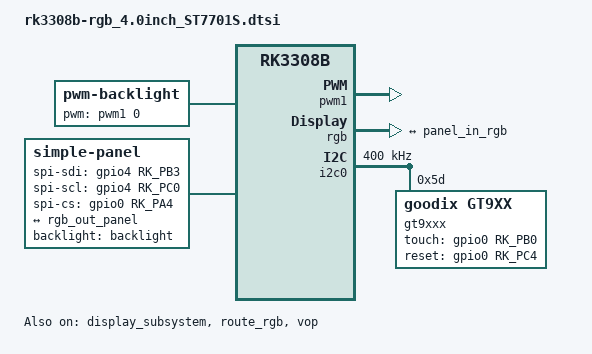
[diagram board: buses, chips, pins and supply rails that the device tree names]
// SPDX-License-Identifier: (GPL-2.0+ OR MIT)
/*
 * Copyright (c) 2018 Fuzhou Rockchip Electronics Co., Ltd
 *
 */

/ {
	backlight: backlight {
		status = "okay";
		compatible = "pwm-backlight";
		pwms = <&pwm1 0 50000 0>;
		brightness-levels = <
			  0   1   2   3   4   5   6   7
			  8   9  10  11  12  13  14  15
			 16  17  18  19  20  21  22  23
			 24  25  26  27  28  29  30  31
			 32  33  34  35  36  37  38  39
			 40  41  42  43  44  45  46  47
			 48  49  50  51  52  53  54  55
			 56  57  58  59  60  61  62  63
			 64  65  66  67  68  69  70  71
			 72  73  74  75  76  77  78  79
			 80  81  82  83  84  85  86  87
			 88  89  90  91  92  93  94  95
			 96  97  98  99 100 101 102 103
			104 105 106 107 108 109 110 111
			112 113 114 115 116 117 118 119
			120 121 122 123 124 125 126 127
			128 129 130 131 132 133 134 135
			136 137 138 139 140 141 142 143
			144 145 146 147 148 149 150 151
			152 153 154 155 156 157 158 159
			160 161 162 163 164 165 166 167
			168 169 170 171 172 173 174 175
			176 177 178 179 180 181 182 183
			184 185 186 187 188 189 190 191
			192 193 194 195 196 197 198 199
			200 201 202 203 204 205 206 207
			208 209 210 211 212 213 214 215
			216 217 218 219 220 221 222 223
			224 225 226 227 228 229 230 231
			232 233 234 235 236 237 238 239
			240 241 242 243 244 245 246 247
			248 249 250 251 252 253 254 255>;
		default-brightness-level = <200>;
	};

	panel: panel {
		compatible = "simple-panel";
		bus-format = <MEDIA_BUS_FMT_RGB888_1X24>;
		backlight = <&backlight>;
        init-delay-ms = <200>;
        rgb-mode = "p888";
		width-mm = <72>;
		height-mm = <72>;
		status = "okay";
        
        spi-sdi-gpios = <&gpio4 RK_PB3 GPIO_ACTIVE_HIGH>;
        spi-scl-gpios = <&gpio4 RK_PC0 GPIO_ACTIVE_HIGH>;
        spi-cs-gpios = <&gpio0 RK_PA4 GPIO_ACTIVE_HIGH>;

        pinctrl-names = "default";
        pinctrl-0 = <&spi_init_cmd>;
        rockchip,cmd-type = "spi";
        /* type:0 is cmd, 1 is data */
        panel-init-sequence = [
            /* type delay num val1 val2 val3 */                                                                                                                                                         
            00   78  01  11
            00   01  01  ff
            01   01  01  77
            01   01  01  01
            01   01  01  00
            01   01  01  00
            01   01  01  10

            00   01  01  c0
            01   01  01  3b
            01   01  01  00

            00   01  01  c1
            01   01  01  0d
            01   01  01  02

            00   01  01  c2
            01   01  01  21
            01   01  01  08

            00   01  01  b0
            01   01  01  00
            01   01  01  11
            01   01  01  18
            01   01  01  0e
            01   01  01  11
            01   01  01  06
            01   01  01  07
            01   01  01  08
            01   01  01  07
            01   01  01  22
            01   01  01  04
            01   01  01  12
            01   01  01  0f
            01   01  01  aa
            01   01  01  31
            01   01  01  18

            00   01  01  b1
            01   01  01  00
            01   01  01  11
            01   01  01  19
            01   01  01  0e
            01   01  01  12
            01   01  01  07
            01   01  01  08
            01   01  01  08
            01   01  01  08
            01   01  01  22
            01   01  01  04
            01   01  01  11
            01   01  01  11
            01   01  01  a9
            01   01  01  32
            01   01  01  18

            00   01  01  ff
            01   01  01  77
            01   01  01  01
            01   01  01  00
            01   01  01  00
            01   01  01  11

            00   01  01  b0
            01   01  01  60

            00   01  01  b1
            01   01  01  30

            00   01  01  b2
            01   01  01  87

            00   01  01  b3
            01   01  01  80

            00   01  01  b5
            01   01  01  49

            00   01  01  b7
            01   01  01  85

            00   01  01  b8
            01   01  01  21

            00   01  01  c1
            01   01  01  02
            01   01  01  0a

            00   01  01  c2
            01   14  01  78

            00   01  01  e0
            01   01  01  00
            01   01  01  1b
            01   01  01  02

            00   01  01  e1
            01   01  01  08
            01   01  01  a0
            01   01  01  00
            01   01  01  00
            01   01  01  07
            01   01  01  a0
            01   01  01  00
            01   01  01  00
            01   01  01  00
            01   01  01  44
            01   01  01  44

            00   01  01  e2
            01   01  01  11
            01   01  01  11
            01   01  01  44
            01   01  01  44
            01   01  01  ed
            01   01  01  a0
            01   01  01  00
            01   01  01  00
            01   01  01  ec
            01   01  01  a0
            01   01  01  00
            01   01  01  00

            00   01  01  e3
            01   01  01  00
            01   01  01  00
            01   01  01  11
            01   01  01  11

            00   01  01  e4
            01   01  01  44
            01   01  01  44

            00   01  01  e5
            01   01  01  0a
            01   01  01  e9
            01   01  01  d8
            01   01  01  a0
            01   01  01  0c
            01   01  01  eb
            01   01  01  d8
            01   01  01  a0
            01   01  01  0e
            01   01  01  ed
            01   01  01  d8
            01   01  01  a0
            01   01  01  10
            01   01  01  ef
            01   01  01  d8
            01   01  01  a0

            00   01  01  e6
            01   01  01  00
            01   01  01  00
            01   01  01  11
            01   01  01  11

            00   01  01  e7
            01   01  01  44
            01   01  01  44

            00   01  01  e8
            01   01  01  09

            01   01  01  e8
            01   01  01  d8
            01   01  01  a0
            01   01  01  0b
            01   01  01  ea
            01   01  01  d8
            01   01  01  a0
            01   01  01  0d
            01   01  01  ec
            01   01  01  d8
            01   01  01  a0
            01   01  01  0f
            01   01  01  ee
            01   01  01  d8
            01   01  01  a0

            00   01  01  eb
            01   01  01  02
            01   01  01  00
            01   01  01  e4
            01   01  01  e4
            01   01  01  88
            01   01  01  00
            01   01  01  40

            00   01  01  ec
            01   01  01  3c
            01   01  01  00

            00   01  01  ed
            01   01  01  ab
            01   01  01  89
            01   01  01  76
            01   01  01  54
            01   01  01  02
            01   01  01  ff
            01   01  01  ff
            01   01  01  ff
            01   01  01  ff
            01   01  01  ff
            01   01  01  ff
            01   01  01  20
            01   01  01  45
            01   01  01  67
            01   01  01  98
            01   01  01  ba

            00   01  01  ff
            01   01  01  77
            01   01  01  01
            01   01  01  00
            01   01  01  00
            01   01  01  00

            00   01  01  3a
            01   01  01  70

            00   01  01  36
            01   01  01  00

            00   01  01  29
            ];

		display-timings {
			native-mode = <&hc480480tft40_timing>;

			hc480480tft40_timing: timing0 {
				clock-frequency = <17000000>;
				hactive = <480>;
				vactive = <480>;
				hback-porch = <15>;
				hfront-porch = <10>;
				vback-porch = <8>;
				vfront-porch = <6>;
				hsync-len = <2>;
				vsync-len = <2>;
                hsync-active = <0>;
                vsync-active = <0>;
                de-active = <0>;
                pixelclk-active = <0>;

			};
		};

		port {
			panel_in_rgb: endpoint {
				remote-endpoint = <&rgb_out_panel>;
			};
		};
	};
};

&display_subsystem {
	status = "okay";
};

&pwm1 {
	status = "okay";
};
&pinctrl {
    spi_panel {
    spi_init_cmd: spi-init-cmd {
                  rockchip,pins =
                      /* spi sdi */
                      <4 RK_PB3 RK_FUNC_GPIO &pcfg_pull_none>,
                      /* spi scl */
                      <4 RK_PC0 RK_FUNC_GPIO &pcfg_pull_none>,
                      /* spi cs */
                      <0 RK_PA4 RK_FUNC_GPIO &pcfg_pull_none>;
              };
    };
};

&rgb {
	status = "okay";
	pinctrl-names = "default";
	pinctrl-0 = <&lcdc_ctl &lcdc_rgb888_m0>;

	ports {
		rgb_out: port@1 {
			reg = <1>;
			#address-cells = <1>;
			#size-cells = <0>;

			rgb_out_panel: endpoint@0 {
				reg = <0>;
				remote-endpoint = <&panel_in_rgb>;
			};
		};
	};
};

&route_rgb {
	status = "okay";
};

&vop {
	status = "okay";
};

&i2c0 {
    status = "okay";
    clock-frequency = <400000>;
    gt9xxx@5d {
        compatible = "goodix,gt9xx";
        reg = <0x5d>;
        touch-gpio = <&gpio0 RK_PB0 IRQ_TYPE_LEVEL_LOW>;
        reset-gpio = <&gpio0 RK_PC4 GPIO_ACTIVE_HIGH>;
        max-x = <480>;
        max-y = <480>;
        tp-size = <40>;
        status = "okay";
    };
};
